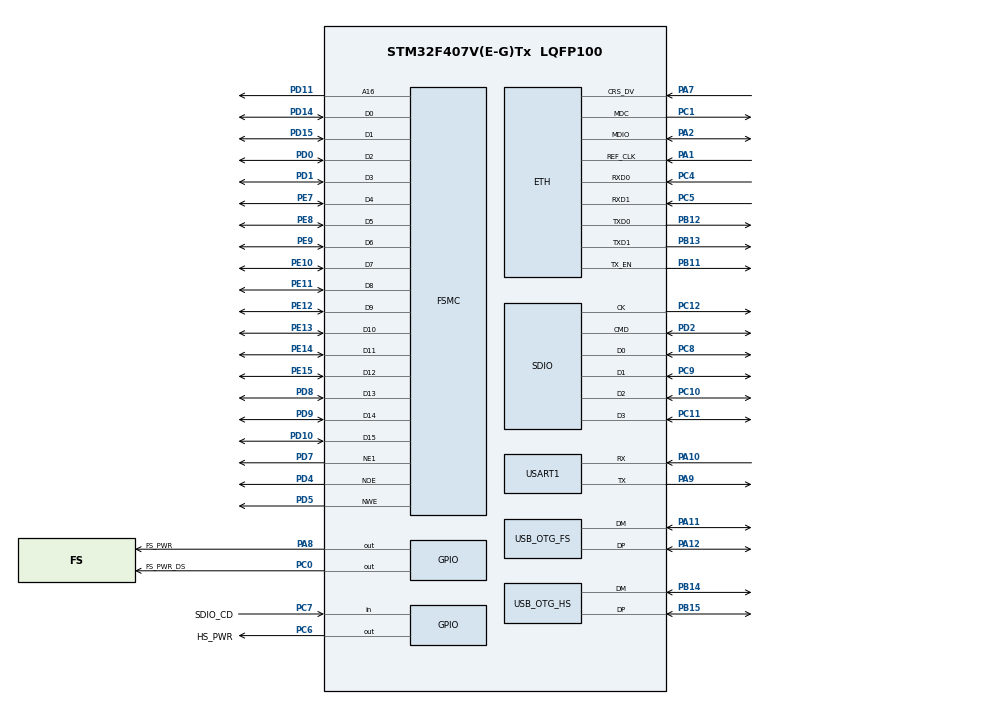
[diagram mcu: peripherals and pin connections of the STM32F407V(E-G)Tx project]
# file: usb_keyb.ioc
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ETH.MediaInterface=ETH_MEDIA_INTERFACE_RMII
FATFS.BSP.number=1
FATFS._CODE_PAGE=855
FATFS._FS_LOCK=0
FATFS._FS_MINIMIZE=3
FATFS._FS_READONLY=1
FATFS._HUSBH=hUsbHostFS
FATFS._USE_FIND=1
FATFS._USE_MKFS=0
FATFS._USE_STRFUNC=0
FATFS0.BSP.STBoard=false
FATFS0.BSP.api=UnknownBspDriver
FATFS0.BSP.i2caddr=0
FATFS0.BSP.i2creg=0
FATFS0.BSP.instance=PC7
FATFS0.BSP.ip=GPIO
FATFS0.BSP.mode=Input
FATFS0.BSP.name=Detect_SDIO
FATFS0.BSP.solution=PC7
FREERTOS.INCLUDE_uxTaskPriorityGet=0
FREERTOS.INCLUDE_vTaskDelete=0
FREERTOS.MEMORY_ALLOCATION=0
FREERTOS.Mutexes01=mtx_hid,Dynamic,NULL;mtx_matrix,Dynamic,NULL;mtx_gui,Dynamic,NULL
FREERTOS.Tasks01=USB,0,128,task_USB,Default,NULL,Dynamic,NULL,NULL;GUI,-3,128,task_GUI,Default,NULL,Dynamic,NULL,NULL;Matrix,-3,128,task_matrix,Default,NULL,Dynamic,NULL,NULL;PS2,-3,128,task_ps2,Default,NULL,Dynamic,NULL,NULL;zxbus,-3,128,task_zxbus,Default,NULL,Dynamic,NULL,NULL
FREERTOS.configMAX_TASK_NAME_LEN=16
FSMC.AddressSetupTime1=8
FSMC.BusTurnAroundDuration1=8
FSMC.DataSetupTime1=1
LWIP.IP_ADDRESS=192.168.001.140
LWIP.LWIP_DHCP=0
LWIP.LWIP_HTTPD=1
LWIP.NETMASK_ADDRESS=255.255.255.000
LWIP.Version=v2.0.3_Cube
Mcu.Family=STM32F4
Mcu.Name=STM32F407V(E-G)Tx
Mcu.Package=LQFP100
NVIC.ETH_IRQn=true\:5\:0\:false\:false\:true\:true\:false
NVIC.OTG_FS_IRQn=true\:5\:0\:false\:false\:true\:true\:false
NVIC.OTG_HS_IRQn=true\:5\:0\:false\:false\:true\:true\:false
NVIC.PriorityGroup=NVIC_PRIORITYGROUP_4
NVIC.TIM1_UP_TIM10_IRQn=true\:0\:0\:false\:false\:true\:false\:false
NVIC.TIM4_IRQn=true\:5\:0\:false\:false\:true\:true\:true
NVIC.TimeBase=TIM1_UP_TIM10_IRQn
NVIC.TimeBaseIP=TIM1
PA1.Mode=RMII
PA1.Signal=ETH_REF_CLK
PA10.Mode=Asynchronous
PA10.Signal=USART1_RX
PA11.Mode=Host_Only
PA11.Signal=USB_OTG_FS_DM
PA12.Mode=Host_Only
PA12.Signal=USB_OTG_FS_DP
PA13.Mode=Serial_Wire
PA13.Signal=SYS_JTMS-SWDIO
PA14.Mode=Serial_Wire
PA14.Signal=SYS_JTCK-SWCLK
PA2.Mode=RMII
PA2.Signal=ETH_MDIO
PA7.Mode=RMII
PA7.Signal=ETH_CRS_DV
PA8.GPIO_Label=FS_PWR
PA8.Signal=GPIO_Output
PA9.Mode=Asynchronous
PA9.Signal=USART1_TX
PB11.Mode=RMII
PB11.Signal=ETH_TX_EN
PB12.Mode=RMII
PB12.Signal=ETH_TXD0
PB13.Mode=RMII
PB13.Signal=ETH_TXD1
PB14.Mode=Host_FS
PB14.Signal=USB_OTG_HS_DM
PB15.Mode=Host_FS
PB15.Signal=USB_OTG_HS_DP
PC0.GPIO_Label=FS_PWR_DS
PC0.Signal=GPIO_Output
PC1.Mode=RMII
PC1.Signal=ETH_MDC
PC10.Mode=SD_4_bits_Wide_bus
PC10.Signal=SDIO_D2
PC11.Mode=SD_4_bits_Wide_bus
PC11.Signal=SDIO_D3
PC12.Mode=SD_4_bits_Wide_bus
PC12.Signal=SDIO_CK
PC4.Mode=RMII
PC4.Signal=ETH_RXD0
PC5.Mode=RMII
PC5.Signal=ETH_RXD1
PC6.GPIO_Label=HS_PWR
PC6.Signal=GPIO_Output
PC7.GPIO_Label=SDIO_CD
PC7.Signal=GPIO_Input
PC8.Mode=SD_4_bits_Wide_bus
PC8.Signal=SDIO_D0
PC9.Mode=SD_4_bits_Wide_bus
PC9.Signal=SDIO_D1
PD0.Mode=16b-d1
PD0.Signal=FSMC_D2
PD1.Mode=16b-d1
PD1.Signal=FSMC_D3
PD10.Mode=16b-d1
PD10.Signal=FSMC_D15
PD11.Mode=A16_1
PD11.Signal=FSMC_A16
PD14.Mode=16b-d1
PD14.Signal=FSMC_D0
PD15.Mode=16b-d1
PD15.Signal=FSMC_D1
PD2.Mode=SD_4_bits_Wide_bus
PD2.Signal=SDIO_CMD
PD3.Signal=USART2_CTS
PD4.Mode=Lcd1
PD4.Signal=FSMC_NOE
PD5.Mode=Lcd1
PD5.Signal=FSMC_NWE
PD6.Signal=USART2_RX
PD7.Mode=NorPsramChipSelect1_1
PD7.Signal=FSMC_NE1
PD8.Mode=16b-d1
PD8.Signal=FSMC_D13
PD9.Mode=16b-d1
PD9.Signal=FSMC_D14
PE10.Mode=16b-d1
PE10.Signal=FSMC_D7
PE11.Mode=16b-d1
PE11.Signal=FSMC_D8
PE12.Mode=16b-d1
PE12.Signal=FSMC_D9
PE13.Mode=16b-d1
PE13.Signal=FSMC_D10
PE14.Mode=16b-d1
PE14.Signal=FSMC_D11
PE15.Mode=16b-d1
PE15.Signal=FSMC_D12
PE7.Mode=16b-d1
PE7.Signal=FSMC_D4
PE8.Mode=16b-d1
PE8.Signal=FSMC_D5
PE9.Mode=16b-d1
PE9.Signal=FSMC_D6
PH0-OSC_IN.Mode=HSE-External-Oscillator
PH0-OSC_IN.Signal=RCC_OSC_IN
PH1-OSC_OUT.Mode=HSE-External-Oscillator
PH1-OSC_OUT.Signal=RCC_OSC_OUT
ProjectManager.HeapSize=0x200
ProjectManager.StackSize=0x400
ProjectManager.TargetToolchain=MDK-ARM V5
RCC.48MHZClocksFreq_Value=48000000
RCC.AHBFreq_Value=168000000
RCC.APB1CLKDivider=RCC_HCLK_DIV4
RCC.APB1Freq_Value=42000000
RCC.APB1TimFreq_Value=84000000
RCC.APB2CLKDivider=RCC_HCLK_DIV2
RCC.APB2Freq_Value=84000000
RCC.APB2TimFreq_Value=168000000
RCC.CortexFreq_Value=168000000
RCC.HCLKFreq_Value=168000000
RCC.HSE_VALUE=8000000
RCC.HSI_VALUE=16000000
RCC.LSE_VALUE=32768
RCC.PLLM=4
RCC.PLLN=168
RCC.PLLQ=7
RCC.SYSCLKFreq_VALUE=168000000
RCC.SYSCLKSource=RCC_SYSCLKSOURCE_PLLCLK
RCC.VCOOutputFreq_Value=336000000
TIM4.Period=200
TIM4.Prescaler=42000
USART1.VirtualMode=VM_ASYNC
USB_HOST.BSP.number=2
USB_HOST.USBH_HandleTypeDef-ALL_Classes_FS=hUsbHostFS
USB_HOST.USBH_HandleTypeDef-ALL_Classes_HS=hUsbHostHS
USB_HOST.VirtualModeFS=All_Classes
USB_HOST.VirtualModeHS=All_Classes
USB_HOST0.BSP.STBoard=false
USB_HOST0.BSP.api=UnknownBspDriver
USB_HOST0.BSP.i2caddr=0
USB_HOST0.BSP.i2creg=0
USB_HOST0.BSP.instance=PC0
USB_HOST0.BSP.ip=GPIO
USB_HOST0.BSP.mode=Output
USB_HOST0.BSP.name=Drive_VBUS_FS
USB_HOST0.BSP.solution=PC0
USB_HOST1.BSP.STBoard=false
USB_HOST1.BSP.api=UnknownBspDriver
USB_HOST1.BSP.i2caddr=0
USB_HOST1.BSP.i2creg=0
USB_HOST1.BSP.instance=PC6
USB_HOST1.BSP.ip=GPIO
USB_HOST1.BSP.mode=Output
USB_HOST1.BSP.name=Drive_VBUS_HS
USB_HOST1.BSP.solution=PC6
USB_OTG_FS.VirtualMode=Host_Only
USB_OTG_FS.phy_itface=HCD_PHY_EMBEDDED
USB_OTG_FS.speed=HCD_SPEED_LOW
USB_OTG_HS.VirtualMode-Host_FS=Host_FS
VP_FATFS_VS_SDIO.Mode=SDIO
VP_FATFS_VS_USB.Mode=USB
VP_FREERTOS_VS_ENABLE.Mode=Enabled
VP_IWDG_VS_IWDG.Mode=IWDG_Activate
VP_LWIP_VS_Enabled.Mode=Enabled
VP_SYS_VS_tim1.Mode=TIM1
VP_TIM4_VS_ClockSourceINT.Mode=Internal
VP_USB_HOST_VS_USB_HOST_ALL_CLASS_FS.Mode=ALL_Classes_FS
VP_USB_HOST_VS_USB_HOST_ALL_CLASS_HS.Mode=ALL_Classes_HS
board=usb_keyb

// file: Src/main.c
/**
  ******************************************************************************
  * @file           : main.c
  * @brief          : Main program body
  ******************************************************************************
  * This notice applies to any and all portions of this file
  * that are not between comment pairs USER CODE BEGIN and
  * USER CODE END. Other portions of this file, whether
  * inserted by the user or by software development tools
  * are owned by their respective copyright owners.
  *
  * Copyright (c) 2018 STMicroelectronics International N.V.
  * All rights reserved.
  *
  * Redistribution and use in source and binary forms, with or without
  * modification, are permitted, provided that the following conditions are met:
  *
  * 1. Redistribution of source code must retain the above copyright notice,
  *    this list of conditions and the following disclaimer.
  * 2. Redistributions in binary form must reproduce the above copyright notice,
  *    this list of conditions and the following disclaimer in the documentation
  *    and/or other materials provided with the distribution.
  * 3. Neither the name of STMicroelectronics nor the names of other
  *    contributors to this software may be used to endorse or promote products
  *    derived from this software without specific written permission.
  * 4. This software, including modifications and/or derivative works of this
  *    software, must execute solely and exclusively on microcontroller or
  *    microprocessor devices manufactured by or for STMicroelectronics.
  * 5. Redistribution and use of this software other than as permitted under
  *    this license is void and will automatically terminate your rights under
  *    this license.
  *
  * THIS SOFTWARE IS PROVIDED BY STMICROELECTRONICS AND CONTRIBUTORS "AS IS"
  * AND ANY EXPRESS, IMPLIED OR STATUTORY WARRANTIES, INCLUDING, BUT NOT
  * LIMITED TO, THE IMPLIED WARRANTIES OF MERCHANTABILITY, FITNESS FOR A
  * PARTICULAR PURPOSE AND NON-INFRINGEMENT OF THIRD PARTY INTELLECTUAL PROPERTY
  * RIGHTS ARE DISCLAIMED TO THE FULLEST EXTENT PERMITTED BY LAW. IN NO EVENT
  * SHALL STMICROELECTRONICS OR CONTRIBUTORS BE LIABLE FOR ANY DIRECT, INDIRECT,
  * INCIDENTAL, SPECIAL, EXEMPLARY, OR CONSEQUENTIAL DAMAGES (INCLUDING, BUT NOT
  * LIMITED TO, PROCUREMENT OF SUBSTITUTE GOODS OR SERVICES; LOSS OF USE, DATA,
  * OR PROFITS; OR BUSINESS INTERRUPTION) HOWEVER CAUSED AND ON ANY THEORY OF
  * LIABILITY, WHETHER IN CONTRACT, STRICT LIABILITY, OR TORT (INCLUDING
  * NEGLIGENCE OR OTHERWISE) ARISING IN ANY WAY OUT OF THE USE OF THIS SOFTWARE,
  * EVEN IF ADVISED OF THE POSSIBILITY OF SUCH DAMAGE.
  *
  ******************************************************************************
  */
#include "main.h"
#include "stm32f4xx_hal.h"
#include "cmsis_os.h"
#include "fatfs.h"
#include "lwip.h"
#include "usb_host.h"

/* USER CODE BEGIN Includes */
#include "gui_all.h"
/* USER CODE END Includes */

SD_HandleTypeDef hsd;

SRAM_HandleTypeDef hsram1;

osThreadId USBHandle;
osThreadId GUIHandle;
osThreadId MatrixHandle;
osThreadId PS2Handle;
osThreadId zxbusHandle;
osMutexId mtx_hidHandle;
osMutexId mtx_matrixHandle;
osMutexId mtx_guiHandle;

/* USER CODE BEGIN PV */
/* Private variables ---------------------------------------------------------*/

/* USER CODE END PV */

void SystemClock_Config(void);
static void MX_GPIO_Init(void);
static void MX_FSMC_Init(void);
static void MX_IWDG_Init(void);
static void MX_SDIO_SD_Init(void);
static void MX_USART1_UART_Init(void);
static void MX_TIM4_Init(void);
void task_USB(void const * argument);
void task_GUI(void const * argument);
void task_matrix(void const * argument);
void task_ps2(void const * argument);
void task_zxbus(void const * argument);

/* USER CODE BEGIN PFP */
/* Private function prototypes -----------------------------------------------*/
void LCD_fill_mem(void);
/* USER CODE END PFP */

int main(void)
{

  /* MCU Configuration----------------------------------------------------------*/

  /* Reset of all peripherals, Initializes the Flash interface and the Systick. */
  HAL_Init();

  /* Configure the system clock */
  SystemClock_Config();

  /* Initialize all configured peripherals */
  MX_GPIO_Init();
  MX_FSMC_Init();
  //MX_IWDG_Init();
  MX_SDIO_SD_Init();
  MX_USART1_UART_Init();
  MX_TIM4_Init();

  /* Create the mutex(es) */
  /* definition and creation of mtx_hid */
  osMutexDef(mtx_hid);
  mtx_hidHandle = osMutexCreate(osMutex(mtx_hid));

  /* definition and creation of mtx_matrix */
  osMutexDef(mtx_matrix);
  mtx_matrixHandle = osMutexCreate(osMutex(mtx_matrix));

  /* definition and creation of mtx_gui */
  osMutexDef(mtx_gui);
  mtx_guiHandle = osMutexCreate(osMutex(mtx_gui));

  /* Create the thread(s) */
  /* definition and creation of USB */
  osThreadDef(USB, task_USB, osPriorityNormal, 0, 128);
  USBHandle = osThreadCreate(osThread(USB), NULL);

  /* definition and creation of GUI */
  osThreadDef(GUI, task_GUI, osPriorityIdle, 0, 128);
  GUIHandle = osThreadCreate(osThread(GUI), NULL);

  /* definition and creation of Matrix */
  osThreadDef(Matrix, task_matrix, osPriorityIdle, 0, 128);
  MatrixHandle = osThreadCreate(osThread(Matrix), NULL);

  /* definition and creation of PS2 */
  osThreadDef(PS2, task_ps2, osPriorityIdle, 0, 128);
  PS2Handle = osThreadCreate(osThread(PS2), NULL);

  /* definition and creation of zxbus */
  osThreadDef(zxbus, task_zxbus, osPriorityIdle, 0, 128);
  zxbusHandle = osThreadCreate(osThread(zxbus), NULL);

  /* Start scheduler */
  osKernelStart();

  /* We should never get here as control is now taken by the scheduler */

  /* Infinite loop */
  while (1)
  {

  }

}

void SystemClock_Config(void)
{

  LL_FLASH_SetLatency(LL_FLASH_LATENCY_5);

  if(LL_FLASH_GetLatency() != LL_FLASH_LATENCY_5)
  {
  Error_Handler();
  }
  LL_PWR_SetRegulVoltageScaling(LL_PWR_REGU_VOLTAGE_SCALE1);

  LL_RCC_HSE_Enable();

   /* Wait till HSE is ready */
  while(LL_RCC_HSE_IsReady() != 1)
  {

  }
  LL_RCC_LSI_Enable();

   /* Wait till LSI is ready */
  while(LL_RCC_LSI_IsReady() != 1)
  {

  }
  LL_RCC_PLL_ConfigDomain_SYS(LL_RCC_PLLSOURCE_HSE, LL_RCC_PLLM_DIV_4, 168, LL_RCC_PLLP_DIV_2);

  LL_RCC_PLL_ConfigDomain_48M(LL_RCC_PLLSOURCE_HSE, LL_RCC_PLLM_DIV_4, 168, LL_RCC_PLLQ_DIV_7);

  LL_RCC_PLL_Enable();

   /* Wait till PLL is ready */
  while(LL_RCC_PLL_IsReady() != 1)
  {

  }
  LL_RCC_SetAHBPrescaler(LL_RCC_SYSCLK_DIV_1);

  LL_RCC_SetAPB1Prescaler(LL_RCC_APB1_DIV_4);

  LL_RCC_SetAPB2Prescaler(LL_RCC_APB2_DIV_2);

  LL_RCC_SetSysClkSource(LL_RCC_SYS_CLKSOURCE_PLL);

   /* Wait till System clock is ready */
  while(LL_RCC_GetSysClkSource() != LL_RCC_SYS_CLKSOURCE_STATUS_PLL)
  {

  }
  LL_Init1msTick(168000000);

  LL_SYSTICK_SetClkSource(LL_SYSTICK_CLKSOURCE_HCLK);

  LL_SetSystemCoreClock(168000000);

  /* SysTick_IRQn interrupt configuration */
  NVIC_SetPriority(SysTick_IRQn, NVIC_EncodePriority(NVIC_GetPriorityGrouping(),15, 0));
}

/* IWDG init function */
static void MX_IWDG_Init(void)
{

  LL_IWDG_Enable(IWDG);

  LL_IWDG_EnableWriteAccess(IWDG);

  LL_IWDG_SetPrescaler(IWDG, LL_IWDG_PRESCALER_4);

  LL_IWDG_SetReloadCounter(IWDG, 4095);

  while (LL_IWDG_IsReady(IWDG) != 1)
  {
  }

  LL_IWDG_ReloadCounter(IWDG);

}

/* SDIO init function */
static void MX_SDIO_SD_Init(void)
{

  hsd.Instance = SDIO;
  hsd.Init.ClockEdge = SDIO_CLOCK_EDGE_RISING;
  hsd.Init.ClockBypass = SDIO_CLOCK_BYPASS_DISABLE;
  hsd.Init.ClockPowerSave = SDIO_CLOCK_POWER_SAVE_DISABLE;
  hsd.Init.BusWide = SDIO_BUS_WIDE_1B;
  hsd.Init.HardwareFlowControl = SDIO_HARDWARE_FLOW_CONTROL_DISABLE;
  hsd.Init.ClockDiv = 0;

}

/* TIM4 init function */
static void MX_TIM4_Init(void)
{

  LL_TIM_InitTypeDef TIM_InitStruct;

  /* Peripheral clock enable */
  LL_APB1_GRP1_EnableClock(LL_APB1_GRP1_PERIPH_TIM4);

  /* TIM4 interrupt Init */
  NVIC_SetPriority(TIM4_IRQn, NVIC_EncodePriority(NVIC_GetPriorityGrouping(),5, 0));
  NVIC_EnableIRQ(TIM4_IRQn);

  TIM_InitStruct.Prescaler = 42000;
  TIM_InitStruct.CounterMode = LL_TIM_COUNTERMODE_UP;
  TIM_InitStruct.Autoreload = 200;
  TIM_InitStruct.ClockDivision = LL_TIM_CLOCKDIVISION_DIV1;
  LL_TIM_Init(TIM4, &TIM_InitStruct);

  LL_TIM_SetClockSource(TIM4, LL_TIM_CLOCKSOURCE_INTERNAL);

  LL_TIM_SetTriggerOutput(TIM4, LL_TIM_TRGO_RESET);

  LL_TIM_DisableMasterSlaveMode(TIM4);

}

/* USART1 init function */
static void MX_USART1_UART_Init(void)
{

  LL_USART_InitTypeDef USART_InitStruct;

  LL_GPIO_InitTypeDef GPIO_InitStruct;

  /* Peripheral clock enable */
  LL_APB2_GRP1_EnableClock(LL_APB2_GRP1_PERIPH_USART1);

  /**USART1 GPIO Configuration
  PA9   ------> USART1_TX
  PA10   ------> USART1_RX
  */
  GPIO_InitStruct.Pin = LL_GPIO_PIN_9|LL_GPIO_PIN_10;
  GPIO_InitStruct.Mode = LL_GPIO_MODE_ALTERNATE;
  GPIO_InitStruct.Speed = LL_GPIO_SPEED_FREQ_VERY_HIGH;
  GPIO_InitStruct.OutputType = LL_GPIO_OUTPUT_PUSHPULL;
  GPIO_InitStruct.Pull = LL_GPIO_PULL_UP;
  GPIO_InitStruct.Alternate = LL_GPIO_AF_7;
  LL_GPIO_Init(GPIOA, &GPIO_InitStruct);

  USART_InitStruct.BaudRate = 115200;
  USART_InitStruct.DataWidth = LL_USART_DATAWIDTH_8B;
  USART_InitStruct.StopBits = LL_USART_STOPBITS_1;
  USART_InitStruct.Parity = LL_USART_PARITY_NONE;
  USART_InitStruct.TransferDirection = LL_USART_DIRECTION_TX_RX;
  USART_InitStruct.HardwareFlowControl = LL_USART_HWCONTROL_NONE;
  USART_InitStruct.OverSampling = LL_USART_OVERSAMPLING_16;
  LL_USART_Init(USART1, &USART_InitStruct);

  LL_USART_ConfigAsyncMode(USART1);

  LL_USART_Enable(USART1);

}

/** Configure pins as
        * Analog
        * Input
        * Output
        * EVENT_OUT
        * EXTI
        * Free pins are configured automatically as Analog (this feature is enabled through
        * the Code Generation settings)
     PD3   ------> USART2_CTS
     PD6   ------> USART2_RX
*/
static void MX_GPIO_Init(void)
{

  LL_GPIO_InitTypeDef GPIO_InitStruct;

  /* GPIO Ports Clock Enable */
  LL_AHB1_GRP1_EnableClock(LL_AHB1_GRP1_PERIPH_GPIOE);
  LL_AHB1_GRP1_EnableClock(LL_AHB1_GRP1_PERIPH_GPIOC);
  LL_AHB1_GRP1_EnableClock(LL_AHB1_GRP1_PERIPH_GPIOH);
  LL_AHB1_GRP1_EnableClock(LL_AHB1_GRP1_PERIPH_GPIOA);
  LL_AHB1_GRP1_EnableClock(LL_AHB1_GRP1_PERIPH_GPIOB);
  LL_AHB1_GRP1_EnableClock(LL_AHB1_GRP1_PERIPH_GPIOD);

  /**/
  LL_GPIO_ResetOutputPin(GPIOC, FS_PWR_DS_Pin|HS_PWR_Pin);

  /**/
  LL_GPIO_ResetOutputPin(FS_PWR_GPIO_Port, FS_PWR_Pin);

  /**/
  GPIO_InitStruct.Pin = LL_GPIO_PIN_2|LL_GPIO_PIN_3|LL_GPIO_PIN_4|LL_GPIO_PIN_5
                          |LL_GPIO_PIN_6|LL_GPIO_PIN_0|LL_GPIO_PIN_1;
  GPIO_InitStruct.Mode = LL_GPIO_MODE_ANALOG;
  GPIO_InitStruct.Pull = LL_GPIO_PULL_NO;
  LL_GPIO_Init(GPIOE, &GPIO_InitStruct);

  /**/
  GPIO_InitStruct.Pin = LL_GPIO_PIN_13|LL_GPIO_PIN_14|LL_GPIO_PIN_15|LL_GPIO_PIN_2
                          |LL_GPIO_PIN_3;
  GPIO_InitStruct.Mode = LL_GPIO_MODE_ANALOG;
  GPIO_InitStruct.Pull = LL_GPIO_PULL_NO;
  LL_GPIO_Init(GPIOC, &GPIO_InitStruct);

  /**/
  GPIO_InitStruct.Pin = FS_PWR_DS_Pin|HS_PWR_Pin;
  GPIO_InitStruct.Mode = LL_GPIO_MODE_OUTPUT;
  GPIO_InitStruct.Speed = LL_GPIO_SPEED_FREQ_LOW;
  GPIO_InitStruct.OutputType = LL_GPIO_OUTPUT_PUSHPULL;
  GPIO_InitStruct.Pull = LL_GPIO_PULL_NO;
  LL_GPIO_Init(GPIOC, &GPIO_InitStruct);

  /**/
  GPIO_InitStruct.Pin = LL_GPIO_PIN_0|LL_GPIO_PIN_3|LL_GPIO_PIN_4|LL_GPIO_PIN_5
                          |LL_GPIO_PIN_6|LL_GPIO_PIN_15;
  GPIO_InitStruct.Mode = LL_GPIO_MODE_ANALOG;
  GPIO_InitStruct.Pull = LL_GPIO_PULL_NO;
  LL_GPIO_Init(GPIOA, &GPIO_InitStruct);

  /**/
  GPIO_InitStruct.Pin = LL_GPIO_PIN_0|LL_GPIO_PIN_1|LL_GPIO_PIN_2|LL_GPIO_PIN_10
                          |LL_GPIO_PIN_3|LL_GPIO_PIN_4|LL_GPIO_PIN_5|LL_GPIO_PIN_6
                          |LL_GPIO_PIN_7|LL_GPIO_PIN_8|LL_GPIO_PIN_9;
  GPIO_InitStruct.Mode = LL_GPIO_MODE_ANALOG;
  GPIO_InitStruct.Pull = LL_GPIO_PULL_NO;
  LL_GPIO_Init(GPIOB, &GPIO_InitStruct);

  /**/
  GPIO_InitStruct.Pin = LL_GPIO_PIN_12|LL_GPIO_PIN_13;
  GPIO_InitStruct.Mode = LL_GPIO_MODE_ANALOG;
  GPIO_InitStruct.Pull = LL_GPIO_PULL_NO;
  LL_GPIO_Init(GPIOD, &GPIO_InitStruct);

  /**/
  GPIO_InitStruct.Pin = SDIO_CD_Pin;
  GPIO_InitStruct.Mode = LL_GPIO_MODE_INPUT;
  GPIO_InitStruct.Pull = LL_GPIO_PULL_NO;
  LL_GPIO_Init(SDIO_CD_GPIO_Port, &GPIO_InitStruct);

  /**/
  GPIO_InitStruct.Pin = FS_PWR_Pin;
  GPIO_InitStruct.Mode = LL_GPIO_MODE_OUTPUT;
  GPIO_InitStruct.Speed = LL_GPIO_SPEED_FREQ_LOW;
  GPIO_InitStruct.OutputType = LL_GPIO_OUTPUT_PUSHPULL;
  GPIO_InitStruct.Pull = LL_GPIO_PULL_NO;
  LL_GPIO_Init(FS_PWR_GPIO_Port, &GPIO_InitStruct);

  /**/
  GPIO_InitStruct.Pin = LL_GPIO_PIN_3|LL_GPIO_PIN_6;
  GPIO_InitStruct.Mode = LL_GPIO_MODE_ALTERNATE;
  GPIO_InitStruct.Speed = LL_GPIO_SPEED_FREQ_VERY_HIGH;
  GPIO_InitStruct.OutputType = LL_GPIO_OUTPUT_PUSHPULL;
  GPIO_InitStruct.Pull = LL_GPIO_PULL_NO;
  GPIO_InitStruct.Alternate = LL_GPIO_AF_7;
  LL_GPIO_Init(GPIOD, &GPIO_InitStruct);

}

/* FSMC initialization function */
static void MX_FSMC_Init(void)
{
  FSMC_NORSRAM_TimingTypeDef Timing;

  /** Perform the SRAM1 memory initialization sequence
  */
  hsram1.Instance = FSMC_NORSRAM_DEVICE;
  hsram1.Extended = FSMC_NORSRAM_EXTENDED_DEVICE;
  /* hsram1.Init */
  hsram1.Init.NSBank = FSMC_NORSRAM_BANK1;
  hsram1.Init.DataAddressMux = FSMC_DATA_ADDRESS_MUX_DISABLE;
  hsram1.Init.MemoryType = FSMC_MEMORY_TYPE_SRAM;
  hsram1.Init.MemoryDataWidth = FSMC_NORSRAM_MEM_BUS_WIDTH_16;
  hsram1.Init.BurstAccessMode = FSMC_BURST_ACCESS_MODE_DISABLE;
  hsram1.Init.WaitSignalPolarity = FSMC_WAIT_SIGNAL_POLARITY_LOW;
  hsram1.Init.WrapMode = FSMC_WRAP_MODE_DISABLE;
  hsram1.Init.WaitSignalActive = FSMC_WAIT_TIMING_BEFORE_WS;
  hsram1.Init.WriteOperation = FSMC_WRITE_OPERATION_ENABLE;
  hsram1.Init.WaitSignal = FSMC_WAIT_SIGNAL_DISABLE;
  hsram1.Init.ExtendedMode = FSMC_EXTENDED_MODE_DISABLE;
  hsram1.Init.AsynchronousWait = FSMC_ASYNCHRONOUS_WAIT_DISABLE;
  hsram1.Init.WriteBurst = FSMC_WRITE_BURST_DISABLE;
  hsram1.Init.PageSize = FSMC_PAGE_SIZE_NONE;
  /* Timing */
  Timing.AddressSetupTime = 8;
  Timing.AddressHoldTime = 1;
  Timing.DataSetupTime = 8;
  Timing.BusTurnAroundDuration = 0;
  Timing.CLKDivision = 0;
  Timing.DataLatency = 0;
  Timing.AccessMode = FSMC_ACCESS_MODE_A;
  /* ExtTiming */

  if (HAL_SRAM_Init(&hsram1, &Timing, NULL) != HAL_OK)
  {
    _Error_Handler(__FILE__, __LINE__);
  }

}

/* task_USB function */
void task_USB(void const * argument)
{
  /* init code for FATFS */
  MX_FATFS_Init();

  /* init code for LWIP */
  //MX_LWIP_Init();

  /* init code for USB_HOST */
  MX_USB_HOST_Init();

  for(;;)
  {
    osDelay(1);
  }
}

/* task_GUI function */
void task_GUI(void const * argument)
{
  /* USER CODE BEGIN task_GUI */
	init_GUI();
	main_GUI();
  /* USER CODE END task_GUI */
}

/* task_matrix function */
void task_matrix(void const * argument)
{
  for(;;)
  {
    osDelay(1);
  }
}

/* task_ps2 function */
void task_ps2(void const * argument)
{
  for(;;)
  {
    osDelay(1);
  }
}

/* task_zxbus function */
void task_zxbus(void const * argument)
{
  for(;;)
  {
    osDelay(1);
  }
}

void HAL_TIM_PeriodElapsedCallback(TIM_HandleTypeDef *htim)
{
  if (htim->Instance == TIM1) {
    HAL_IncTick();
  }
  /* USER CODE BEGIN Callback 1 */
  if (htim->Instance == TIM4) {
    LCD_fill_mem();
  }

  /* USER CODE END Callback 1 */
}

void _Error_Handler(char *file, int line)
{
  while(1)
  {
  }
}

/************************ (C) COPYRIGHT STMicroelectronics *****END OF FILE****/
